# MSP430F1611 register map
Registers are 8-bit, read-write, reset 0x0 unless marked. A register's access mark holds for its fields unless they carry their own. Offsets are from the block's base; [hi:lo] are bit positions; lines under a group give offsets from that group; {n}, {i} and the like mark numbered series.

## USART_1
Base 0x00000078
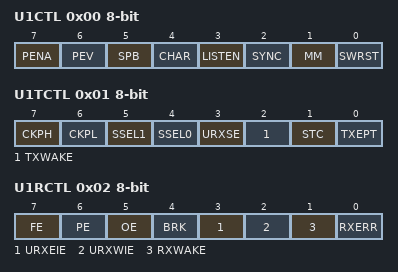
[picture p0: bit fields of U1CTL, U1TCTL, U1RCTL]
0x00 U1CTL — USART 1 Control
  [7] PENA — Parity enable
  [6] PEV — Parity 0:odd / 1:even
  [5] SPB — Stop Bits 0:one / 1: two
  [4] CHAR — Data 0:7-bits / 1:8-bits
  [3] LISTEN — Listen mode
  [2] SYNC — UART / SPI mode
  [1] MM — Master Mode off/on
  [0] SWRST — USART Software Reset
0x01 U1TCTL — USART 1 Transmit Control
  [7] CKPH — SPI: Clock Phase
  [6] CKPL — Clock Polarity
  [5] SSEL1 — Clock Source Select 1
  [4] SSEL0 — Clock Source Select 0
  [3] URXSE — Receive Start edge select
  [2] TXWAKE — TX Wake up mode
  [1] STC — SPI: STC enable 0:on / 1:off
  [0] TXEPT — TX Buffer empty
0x02 U1RCTL — USART 1 Receive Control
  [7] FE — Frame Error
  [6] PE — Parity Error
  [5] OE — Overrun Error
  [4] BRK — Break detected
  [3] URXEIE — RX Error interrupt enable
  [2] URXWIE — RX Wake up interrupt enable
  [1] RXWAKE — RX Wake up detect
  [0] RXERR — RX Error Error
0x03 U1MCTL — USART 1 Modulation Control
0x04 U1BR0 — USART 1 Baud Rate 0
0x05 U1BR1 — USART 1 Baud Rate 1
0x06 U1RXBUF — USART 1 Receive Buffer
0x07 U1TXBUF — USART 1 Transmit Buffer

## ADC12
Base 0x00000080
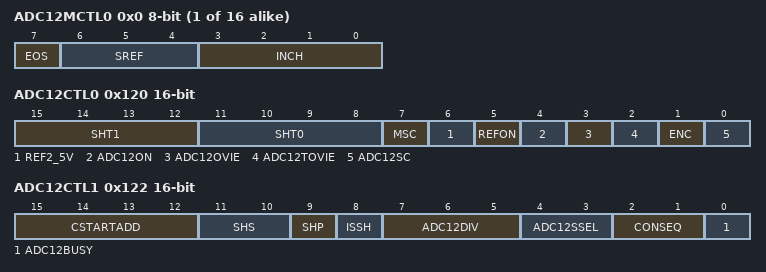
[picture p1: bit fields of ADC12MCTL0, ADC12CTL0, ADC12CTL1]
{0x0+i} ADC12MCTL{i} (i=0..15) — ADC12 Memory Control {i}
  [7] EOS — ADC12 End of Sequence
  [6:4] SREF — ADC12 Select Reference Bit 0
    {v}=ADC12 Select Reference {v} (v=0..7)
  [3:0] INCH — ADC12 Input Channel Select Bit 0
    {v}=ADC12 Input Channel {v} (v=0..15)
{0xC0+2i} ADC12MEM{i} 16-bit (i=0..15) — ADC12 Conversion Memory {i}
0x120 ADC12CTL0 16-bit — ADC12 Control 0
  [15:12] SHT1 — ADC12 Sample Hold 0 Select 0
    {v}=ADC12 Sample Hold 1 Select Bit: {v} (v=0..15)
  [11:8] SHT0 — ADC12 Sample Hold 0 Select 0
    {v}=ADC12 Sample Hold 0 Select Bit: {v} (v=0..15)
  [7] MSC — ADC12 Multiple SampleConversion
  [6] REF2_5V — ADC12 Ref 0:1.5V / 1:2.5V
  [5] REFON — ADC12 Reference on
  [4] ADC12ON — ADC12 On/enable
  [3] ADC12OVIE — ADC12 Overflow interrupt enable
  [2] ADC12TOVIE — ADC12 Timer Overflow interrupt enable
  [1] ENC — ADC12 Enable Conversion
  [0] ADC12SC — ADC12 Start Conversion
0x122 ADC12CTL1 16-bit — ADC12 Control 1
  [15:12] CSTARTADD — ADC12 Conversion Start Address 0
    {v}=ADC12 Conversion Start Address: {v} (v=0..15)
  [11:10] SHS — ADC12 Sample/Hold Source 0
    {v}=ADC12 Sample/Hold Source: {v} (v=0..3)
  [9] SHP — ADC12 Sample/Hold Pulse Mode
  [8] ISSH — ADC12 Invert Sample Hold Signal
  [7:5] ADC12DIV — ADC12 Clock Divider Select 0
    {v}=ADC12 Clock Divider Select: {v} (v=0..7)
  [4:3] ADC12SSEL — ADC12 Clock Source Select 0
    {v}=ADC12 Clock Source Select: {v} (v=0..3)
  [2:1] CONSEQ — ADC12 Conversion Sequence Select 0
    {v}=ADC12 Conversion Sequence Select: {v} (v=0..3)
  [0] ADC12BUSY
0x124 ADC12IFG 16-bit — ADC12 Interrupt Flag
0x126 ADC12IE 16-bit — ADC12 Interrupt Enable
0x128 ADC12IV 16-bit — ADC12 Interrupt Vector Word

## TIMER_B7
Base 0x0000011E
0x00 TBIV 16-bit — Timer B Interrupt Vector Word
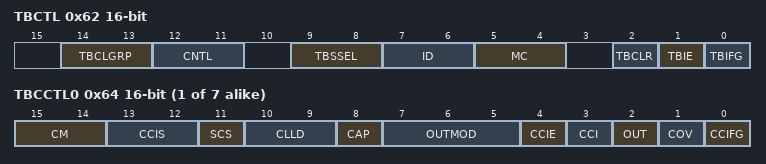
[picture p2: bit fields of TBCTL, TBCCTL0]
0x62 TBCTL 16-bit — Timer B Control
  [14:13] TBCLGRP — Timer B Compare latch load group 1
    0=Timer B Group: 0 - individually; 1=Timer B Group: 1 - 3 groups (1-2; 2=Timer B Group: 2 - 2 groups (1-3; 3=Timer B Group: 3 - 1 group (all)
  [12:11] CNTL — Counter lenght 1
    0=Counter lenght: 16 bit; 1=Counter lenght: 12 bit; 2=Counter lenght: 10 bit; 3=Counter lenght: 8 bit
  [9:8] TBSSEL — Clock source 1
    0=Clock Source: TBCLK; 1=Clock Source: ACLK; 2=Clock Source: SMCLK; 3=Clock Source: INCLK
  [7:6] ID — Timer B clock input divider 1
    0=Timer A input divider: 0 - /1; 1=Timer A input divider: 1 - /2; 2=Timer A input divider: 2 - /4; 3=Timer A input divider: 3 - /8
  [5:4] MC — Timer B mode control 1
    0=Timer A mode control: 0 - Stop; 1=Timer A mode control: 1 - Up to CCR0; 2=Timer A mode control: 2 - Continous up; 3=Timer A mode control: 3 - Up/Down
  [2] TBCLR — Timer B counter clear
  [1] TBIE — Timer B interrupt enable
  [0] TBIFG — Timer B interrupt flag
{0x64+2i} TBCCTL{i} 16-bit (i=0..6) — Timer B Capture/Compare Control {i}
  [15:14] CM — Capture mode 1
    0=Capture mode: 0 - disabled; 1=Capture mode: 1 - pos. edge; 2=Capture mode: 1 - neg. edge; 3=Capture mode: 1 - both edges
  [13:12] CCIS — Capture input select 1
    0=Capture input select: 0 - CCIxA; 1=Capture input select: 1 - CCIxB; 2=Capture input select: 2 - GND; 3=Capture input select: 3 - Vcc
  [11] SCS — Capture sychronize
  [10:9] CLLD — Compare latch load source 1
    0=Compare latch load sourec : 0 - immediate; 1=Compare latch load sourec : 1 - TBR counts to 0; 2=Compare latch load sourec : 2 - up/down; 3=Compare latch load sourec : 3 - TBR counts to TBCTL0
  [8] CAP — Capture mode: 1 /Compare mode : 0
  [7:5] OUTMOD — Output mode 2
    0=PWM output mode: 0 - output only; 1=PWM output mode: 1 - set; 2=PWM output mode: 2 - PWM toggle/reset; 3=PWM output mode: 3 - PWM set/reset; 4=PWM output mode: 4 - toggle; 5=PWM output mode: 5 - Reset; 6=PWM output mode: 6 - PWM toggle/set; 7=PWM output mode: 7 - PWM reset/set
  [4] CCIE — Capture/compare interrupt enable
  [3] CCI — Capture input signal (read)
  [2] OUT — PWM Output signal if output mode 0
  [1] COV — Capture/compare overflow flag
  [0] CCIFG — Capture/compare interrupt flag
0x72 TBR 16-bit — Timer B Counter Register
{0x74+2i} TBCCR{i} 16-bit (i=0..6) — Timer B Capture/Compare {i}
